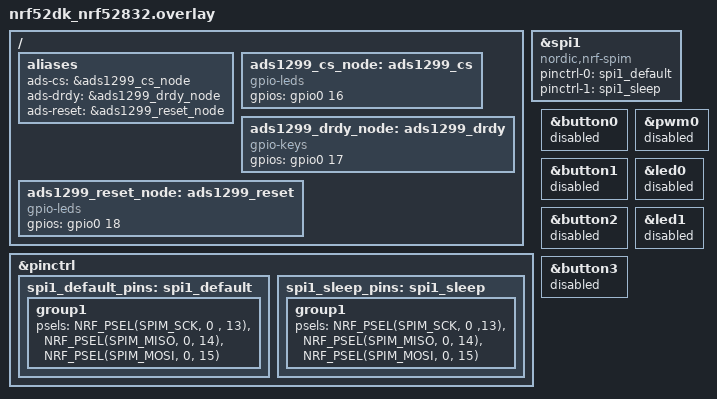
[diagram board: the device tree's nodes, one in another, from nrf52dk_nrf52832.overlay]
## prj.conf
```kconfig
CONFIG_GPIO=y
CONFIG_SPI=y
CONFIG_LOG=y
CONFIG_SOC_NRF52832_ALLOW_SPIM_DESPITE_PAN_58=y
CONFIG_LOG_BACKEND_UART=y
CONFIG_UART_CONSOLE=y
```

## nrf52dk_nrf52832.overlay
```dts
// To get started, press Ctrl+Space to bring up the completion menu and view the available nodes.

// You can also use the buttons in the sidebar to perform actions on nodes.
// Actions currently available include:

// * Enabling / disabling the node
// * Adding the bus to a bus
// * Removing the node
// * Connecting ADC channels

// For more help, browse the DeviceTree documentation at https://docs.zephyrproject.org/latest/guides/dts/index.html
// You can also visit the nRF DeviceTree extension documentation at https://docs.nordicsemi.com/bundle/nrf-connect-vscode/page/guides/ncs_configure_app.html#devicetree-support-in-the-extension
&spi1 {
    compatible  =  "nordic,nrf-spim";
    status      =   "okay";
    pinctrl-0   =   <&spi1_default>;
    pinctrl-1   =   <&spi1_sleep>;
    pinctrl-names = "default", "sleep";
};

&pinctrl {
    spi1_default_pins: spi1_default{
        group1{
            psels = <NRF_PSEL(SPIM_SCK, 0 , 13)>,
                    <NRF_PSEL(SPIM_MISO, 0, 14)>,
                    <NRF_PSEL(SPIM_MOSI, 0, 15)>;
        };
    };

    spi1_sleep_pins: spi1_sleep{
        group1{
            psels = <NRF_PSEL(SPIM_SCK, 0 ,13)>,
                    <NRF_PSEL(SPIM_MISO, 0, 14)>,
                    <NRF_PSEL(SPIM_MOSI, 0, 15)>;
        };
    };
};

&button0 {
    status = "disabled";
};

&button1 {
    status = "disabled";
};

&button2 {
    status = "disabled";
};

&button3 {
    status = "disabled";
};

&pwm0 {
    status = "disabled";
};

&led0 {
    status = "disabled";
};

&led1 {
    status = "disabled";
};

/ {
    aliases {
		ads-cs = &ads1299_cs_node;
		ads-drdy = &ads1299_drdy_node;
		ads-reset = &ads1299_reset_node;
	};

	ads1299_cs_node: ads1299_cs {
        compatible = "gpio-leds";
		gpios = <&gpio0 16 0>;
	};

	ads1299_drdy_node: ads1299_drdy {
        compatible = "gpio-keys";
		gpios = <&gpio0 17 0>;
	};

	ads1299_reset_node: ads1299_reset {
        compatible = "gpio-leds";
		gpios = <&gpio0 18 0>;
	};
    
};  
```

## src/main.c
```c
#include <zephyr/kernel.h>
#include <zephyr/logging/log.h>
#include "ads1299_driver.h"

LOG_MODULE_REGISTER(main, LOG_LEVEL_INF);

void main(void){
        LOG_INF("ADS1299 Device test");
        
        if (ads1299_init(NULL) != 0) {
                LOG_ERR("Failed to initialize ADS1299 driver. Halting.");
                return; // Stop execution if initialization fails
        }
        
        k_sleep(K_MSEC(500));

        LOG_INF("Sending reset command");
        ads1299_send_command(NULL, _RESET);
        k_sleep(K_MSEC(10));

        LOG_INF("Sending STOP continuous data command");
        ads1299_send_command(NULL, _SDATAC);
        k_sleep(K_MSEC(10));

        uint8_t device_id = 0;
        LOG_INF("Reading Device ID Register...");
        int error = ads1299_read_register(NULL, ID, &device_id);

        if(error == 0){
                LOG_INF("Read Succesful. Device ID: 0x%02X", device_id);

                if((device_id & 0xE0) == 0xC0){
                        LOG_INF("Valid Device ID ! SPI communication is working!");
                }
                else{
                        LOG_ERR("Invalid Device ID! Check wiring, power, configuration");
                }
        }
        else{
                LOG_ERR("Failed to read Device ID register. Error %d", error);
        }
}
```

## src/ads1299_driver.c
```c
#include "ads1299_driver.h"
#include <zephyr/drivers/spi.h>
#include <zephyr/drivers/gpio.h>
#include <zephyr/logging/log.h>
#include <zephyr/devicetree.h>

// //register file for logging 
// LOG_MODULE_REGISTER(ads1299_driver, LOG_LEVEL_DBG);

// //device handles from overlay file
// static const struct gpio_dt_spec cs_spec = GPIO_DT_SPEC_GET(DT_ALIAS(ads_cs), gpios);
// static const struct gpio_dt_spec drdy_spec = GPIO_DT_SPEC_GET(DT_ALIAS(ads_drdy), gpios);
// static const struct gpio_dt_spec reset_spec = GPIO_DT_SPEC_GET(DT_ALIAS(ads_reset), gpios);

// static const struct device *spi_dev = DEVICE_DT_GET(DT_NODELABEL(spi1));

// //SPI configuration for ADS1299
// static const struct spi_config spi_cfg = {
//         .operation = SPI_OP_MODE_MASTER | SPI_WORD_SET(8) | SPI_MODE_CPHA,
//         .frequency = 1000000,
// };

// //initialose the ads1299
// int ads1299_init(const struct device *dev){
//     (void)dev;
//     int ret;

//     if(!device_is_ready(cs_spec.port) | !device_is_ready(drdy_spec.port) | !device_is_ready(reset_spec.port)| !device_is_ready(spi_dev)){
//         LOG_ERR("Device is not ready");
//         return -ENODEV;
//     }

//     ret = gpio_pin_configure_dt(&cs_spec, GPIO_OUTPUT_INACTIVE);
//     if(ret < 0){
//         return ret;
//     }
//     ret = gpio_pin_configure_dt(&reset_spec, GPIO_OUTPUT_INACTIVE);
//     if(ret < 0 ){
//         return ret;
//     }
//     ret = gpio_pin_configure_dt(&drdy_spec, GPIO_INPUT);
//     if(ret < 0){
//         return ret;
//     }
//     LOG_INF("ADS1299 sucessfully initialised");
//     return 0;
// }


// //send singly byte command to ads1299
// int ads1299_send_command(const struct device *dev, uint8_t command){
//     (void)dev;

//     struct spi_buf tx_buf = {.buf = &command, .len = 1};
//     struct spi_buf_set tx_set = {.buffers = &tx_buf, .count = 1};

//     gpio_pin_set_dt(&cs_spec, 1); //pull cs pin low
//     k_sleep(K_USEC(1));

//     int error = spi_write(spi_dev, &spi_cfg, &tx_set);
//     if(error) {
//         LOG_ERR("SPI write failed with error %d", error);
//     }

//     k_sleep(K_USEC(1));
//     gpio_pin_set_dt(&cs_spec, 0);
    
//     return error;
// }

// //read from a single register from the ads1299
// int ads1299_read_register(const struct device *dev, uint8_t address, uint8_t *value){
//     (void)dev;

//     uint8_t tx_buffer[2] = {(0x20 | address), 0x00};
//     uint8_t rx_buffer[3]; //3 bytes are needed

//     struct spi_buf tx_bufs[] = {
//         {.buf = &tx_buffer[0], .len = 1},
//         {.buf = &tx_buffer[1], .len = 1}
//     };
//     struct spi_buf_set tx_set = {.buffers = tx_bufs, .count = 2};

//     struct spi_buf rx_bufs[] = {
//         {.buf = NULL, .len = 1},
//         {.buf = NULL, .len = 1},
//         {.buf = value, .len = 1}
//     };
//     struct spi_buf_set rx_set = {.buffers = rx_bufs, .count = 3};

//     gpio_pin_set_dt(&cs_spec, 1);
//     k_sleep(K_USEC(1));

//     int error = spi_transceive(spi_dev, &spi_cfg, &tx_set, &rx_set);
//     if(error) {
//         LOG_ERR("SPI transceive failed with error %d", error);
//     }

//     k_sleep(K_USEC(1));
//     gpio_pin_set_dt(&cs_spec, 0);

//     return error;
// }

// //write a single value to a register on the ads1299
// int ads1299_write_register(const struct device *dev, uint8_t address, uint8_t value){
//     (void)dev;

//     uint8_t tx_buffer[2] = {(0x40 | address), value};

//     struct spi_buf tx_buf = {.buf = tx_buffer, .len = 2};
//     struct spi_buf_set tx_set = {.buffers = &tx_buf, .count = 1};

//     gpio_pin_set_dt(&cs_spec, 1);
//     k_sleep(K_USEC(1));

//     int error = spi_write(spi_dev, &spi_cfg, &tx_set);
//     if(error) {
//         LOG_ERR("SPI write failed with error %d", error);
//     }

//     k_sleep(K_USEC(1));
//     gpio_pin_set_dt(&cs_spec, 0);

//     return error;

// }
```

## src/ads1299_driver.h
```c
//
//  ADS1299.h
//  Part of the Arduino Library
//  Created by Conor Russomanno, Luke Travis, and Joel Murphy. Summer 2013.
//
//  Modified by Chip Audette through April 2014
//

#ifndef ____ADS1299__DRIVER_H
#define ____ADS1299__DRIVER_H

#include <zephyr/device.h>
#include <stdint.h>

//Register and command defintions; these values come from ads1299 datasheet(gemini also said they are universal)

//SPI command definitions
#define _WAKEUP     0x02 //wakeup from standby mode
#define _STANDBY    0x04 //Enter standby mode
#define _RESET      0x06 //reset the device
#define _START      0x08 //Start/restart (synchronise) conversions
#define _STOP       0x0A //stop conversion
#define _RDATAC     0x10 //Enable Read Data Continuous mode
#define _SDATAC     0x11 //Stop Read Data Continuous mode
#define _RDATA      0x12 //Read data by command

//Register Address
#define ID          0x00
#define ADS_CONFIG1 0x01
#define ADS_CONFIG2 0x02
#define ADS_CONFIG3 0x03
#define LOFF        0x04
#define CH1SET      0x05
#define CH2SET      0x06
#define CH3SET      0x07
#define CH4SET      0x08
#define CH5SET      0x09
#define CH6SET      0x0A
#define CH7SET      0x0B
#define CH8SET      0x0C
#define BIAS_SENSP  0x0D
#define BIAS_SENSN  0x0E
#define LOFF_SENSP  0x0F
#define LOFF_SENSN  0x10
#define LOFF_FLIP   0x11
#define LOFF_STATP  0x12
#define LOFF_STATN  0x13
#define GPIO        0x14
#define MISC1       0x15
#define MISC2       0x16
#define CONFIG4     0x17 

//Public function properties; Public API for ads1299 driver; these functions will be called in main c to talk to ads

/*initialise the device, return 0 on success and error code on failure
    parameter:
    *dev -> pointer to the ads1299 device structure
*/
int ads1299_init(const struct device *dev);

/*Send a one byte command to the ads1299
    parameter:
    *dev-> pointer to the ads1299 device structure
    command -> the command byte to send from the above list
*/
int ads1299_send_command(const struct device *dev, uint8_t command);

/*Reads a single register from the ads1299
    parameter:
    *dev -> pointer to the ads1299 device structure
    address -> address of the register from list above
    value -> pointer to a variable where the value will be stored
*/
int ads1299_read_register(const struct device *dev, uint8_t address, uint8_t *value);

/*write a single value to a register in the ads1299
    parameter:
    *dev -> pointer to the ads1299 device structure
    address -> address of the register from the list above
    value -> the value to write to the register
*/
int ads1299_write_register(const struct device *dev, uint8_t address, uint8_t value);


#endif
```
